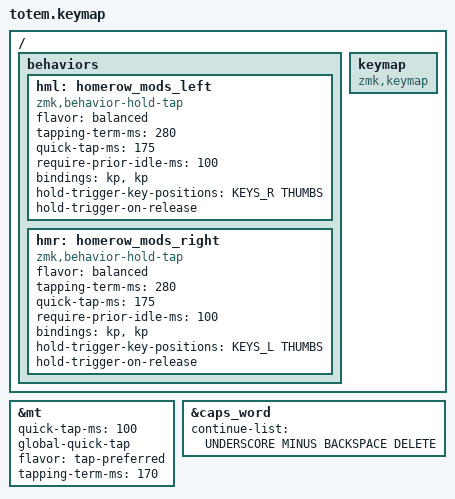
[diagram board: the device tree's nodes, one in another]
//
//                                                        ▀▀▀▀▀     ▀▀▀▀▀          ▀▀█▀▀
//                                                        ▄▀▀▀▄  ▄  ▄▀▀▀▄  ▄  ▄▀▀▀▄  █  ▄▀▀▀▄
//                                                        █   █  █  █   █  █  █   █  █  █   █
//                                                         ▀▀▀   █   ▀▀▀   █   ▀▀▀   ▀   ▀▀▀
//                                                               █      ▄▄▄█▄▄▄    █   █  
//                                                               ▀      █  █  █     █▄█
//                                                             ▀▀▀▀▀    █  █  █      ▀
//                                                                      ▀  ▀  ▀
//
// =================================================================================================
// Magic Sturdy Layout Implementation for Totem Keyboard
// =================================================================================================
//
// Modular configuration - files are organized by functionality:
// - magic_key/: Magic Key functionality (contextual character output)
// - smart_repeat/: Smart Repeat functionality (intelligent repeated character output)
// - czech_leader/: Czech diacritics input using leader key
// - layers/: Keyboard layer definitions
//
// =================================================================================================

#include <behaviors.dtsi>
#include <dt-bindings/zmk/keys.h>
#include <dt-bindings/zmk/bt.h>
#include <dt-bindings/zmk/outputs.h>


// Define HOST_OS as 2 for macOS
#define HOST_OS 2
// includes for zmk helper
#include "zmk-helpers/helper.h"
#include "zmk-helpers/key-labels/totem.h"
#include "zmk-helpers/unicode-chars/czech.dtsi"

// Layer definitions
#define BASE  0
#define BASE2 1
#define NAV   2
#define SYM   3
#define CMD   4
#define ADJ   5

// Customize default behavior settings
&mt {
  quick-tap-ms = <100>;
  global-quick-tap;
  flavor = "tap-preferred";
  tapping-term-ms = <170>;
};

&caps_word {
    continue-list = <UNDERSCORE MINUS BACKSPACE DELETE>;
};

// Define key positions based on the Totem layout
// This helps define which keys are on which hand for hold-trigger positions
#define KEYS_L LT4 LT3 LT2 LT1 LT0 LM4 LM3 LM2 LM1 LM0 LB5 LB4 LB3 LB2 LB1 // left-hand keys
#define KEYS_R RT0 RT1 RT2 RT3 RT4 RM0 RM1 RM2 RM3 RM4 RB0 RB1 RB2 RB3 RB4 // right-hand keys
#define THUMBS LH2 LH1 LH0 RH0 RH1 RH2 // thumb keys

/ {
    // Timeless homerow mods for left hand
    behaviors {
        hml: homerow_mods_left {
            compatible = "zmk,behavior-hold-tap";
            #binding-cells = <2>;
            flavor = "balanced";
            tapping-term-ms = <280>;
            quick-tap-ms = <175>;
            require-prior-idle-ms = <100>;
            bindings = <&kp>, <&kp>;
            hold-trigger-key-positions = <KEYS_R THUMBS>;
            hold-trigger-on-release;
        };

        // Timeless homerow mods for right hand
        hmr: homerow_mods_right {
            compatible = "zmk,behavior-hold-tap";
            #binding-cells = <2>;
            flavor = "balanced";
            tapping-term-ms = <280>;
            quick-tap-ms = <175>;
            require-prior-idle-ms = <100>;
            bindings = <&kp>, <&kp>;
            hold-trigger-key-positions = <KEYS_L THUMBS>;
            hold-trigger-on-release;
        };
    };

    // Import all modular components by functionality
    #include "magic_key/magic_key.dtsi"        // Magic Key functionality
    #include "smart_repeat/smart_repeat.dtsi"  // Smart Repeat functionality
    #include "czech_leader/czech_leader.dtsi"  // Czech Leader functionality
    #include "combos/combos.dtsi"              // Key combinations
    #include "layers/symbol_macros.dtsi"
    
    keymap {
        compatible = "zmk,keymap";
        
        #include "layers/base_layer.dtsi"
        #include "layers/base2_layer.dtsi"
        #include "layers/nav_layer.dtsi"
        #include "layers/sym_layer.dtsi"
        #include "layers/command_layer.dtsi"
        #include "layers/adjust_layer.dtsi"
    };
}; 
